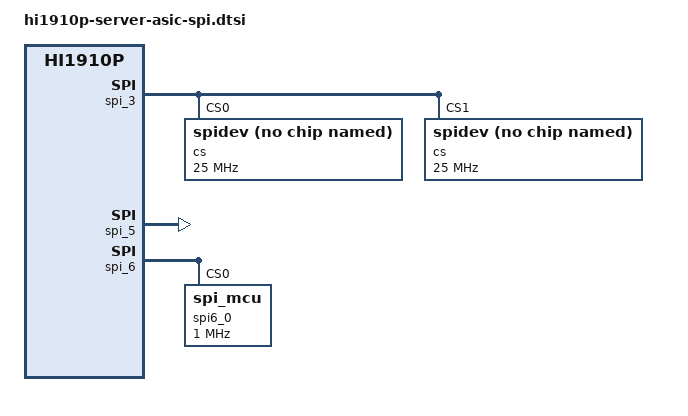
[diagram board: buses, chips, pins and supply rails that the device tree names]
    alg_clk: alg_clk {
        compatible = "fixed-clock";
        #clock-cells = <0>;
        clock-frequency = <200000000>;
    };

    spi_3: spi@A4490000{
	 compatible = "hisi-spi";
	 reg = <0x0 0xA4490000 0 0x10000>;
	 interrupts = <0 122 4>;
	 clocks = <&alg_clk>;
	 clock-names = "spi_clk";
	 num-cs = <3>;
	 id = <3>;
	 status = "ok";
	 pinctrl-names = "default";
	 pinctrl-0 = <&strob10_pmx_func &strob11_pmx_func &strob12_pmx_func
		      &strob13_pmx_func &strob14_pmx_func &strob15_pmx_func>;
	 cs@0 {
		 compatible = "rohm,dh2228fv";
		 reg = <0>; /* cs片选id */
		 spi-max-frequency = <25000000>;
 	 };
         cs@1 {
                 compatible = "rohm,dh2228fv";
                 reg = <1>; /* cs片选id */
                 spi-max-frequency = <25000000>;
         };
 };

    spi_5: spi@A44A0000{
        compatible = "hisi-spi";
        reg = <0x0 0xA44A0000 0 0x10000>;
        interrupts = <0 124 4>;
        clocks = <&alg_clk>;
        clock-names = "spi_clk";
        num-cs = <1>;
        id = <5>;
        status = "ok";
        pinctrl-names = "default";
        pinctrl-0 = <&iomg045_pmx_func &iomg046_pmx_func &iomg047_pmx_func
                     &iomg048_pmx_func>;
    };

    spi_6: spi@A44B0000{
        compatible = "hisi-spi";
        reg = <0x0 0xA44B0000 0 0x10000>;
        interrupts = <0 125 4>;
        clocks = <&alg_clk>;
        clock-names = "spi_clk";
        num-cs = <1>;
        id = <6>;
        status = "ok";
        pinctrl-names = "default";
        pinctrl-0 = <&iomg049_pmx_func &iomg050_pmx_func &iomg051_pmx_func
                     &iomg052_pmx_func>;
        spi6_0: spi_smbus@0 {
            compatible = "spi_mcu";
            reg = <0>;
            spi-max-frequency = <1000000>;
            mode = <0>;
        };
    };
